AUTOSAR XML (schema 4-2-2)
package /ComponentTypes
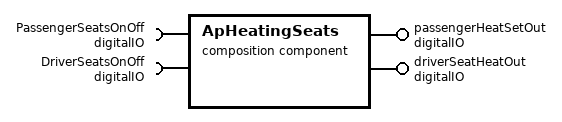
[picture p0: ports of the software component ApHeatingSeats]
  composition sw component type ApHeatingSeats
    require port PassengerSeatsOnOff: required-interface=digitalIO
    require port DriverSeatsOnOff: required-interface=digitalIO
    provide port passengerHeatSetOut: provided-interface=digitalIO
    provide port driverSeatHeatOut: provided-interface=digitalIO
    component HeatedSeatsOut: type=HeatedSeatsOut
    component HeatedSeats: type=HeatedSeats
    delegate HeatedSeatsOut.heatedSeatsOnOff <-> outer port PassengerSeatsOnOff
    delegate HeatedSeatsOut.heatedSeatsOnOff <-> outer port DriverSeatsOnOff
    delegate HeatedSeats.heatedSeatsOnOff <-> outer port passengerHeatSetOut
    delegate HeatedSeats.heatedSeatsOnOff <-> outer port driverSeatHeatOut
